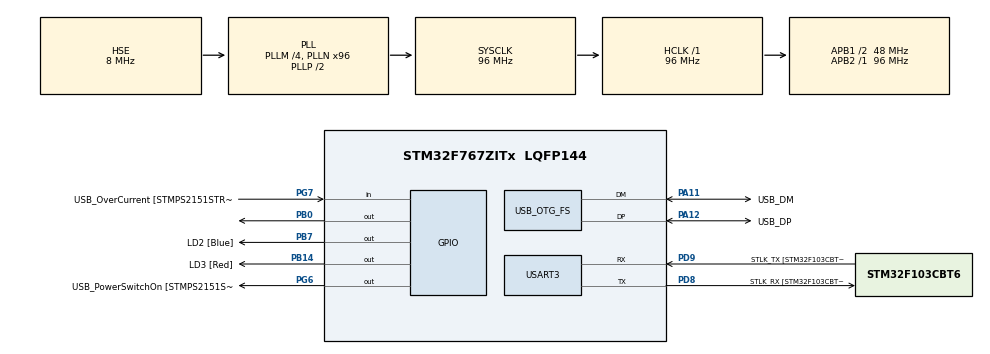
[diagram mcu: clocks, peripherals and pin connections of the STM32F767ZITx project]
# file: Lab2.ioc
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CORTEX_M7.default_mode_Activation=1
Mcu.Family=STM32F7
Mcu.Name=STM32F767ZITx
Mcu.Package=LQFP144
NVIC.OTG_FS_IRQn=true\:0\:0\:false\:false\:true\:false\:true\:true
NVIC.PriorityGroup=NVIC_PRIORITYGROUP_4
PA11.GPIO_Label=USB_DM
PA11.Mode=Device_Only
PA11.Signal=USB_OTG_FS_DM
PA12.GPIO_Label=USB_DP
PA12.Mode=Device_Only
PA12.Signal=USB_OTG_FS_DP
PA13.GPIO_Label=TMS
PA13.Mode=Serial_Wire
PA13.Signal=SYS_JTMS-SWDIO
PA14.GPIO_Label=TCK
PA14.Mode=Serial_Wire
PA14.Signal=SYS_JTCK-SWCLK
PB0.Signal=GPIO_Output
PB14.GPIO_Label=LD3 [Red]
PB14.Signal=GPIO_Output
PB7.GPIO_Label=LD2 [Blue]
PB7.Signal=GPIO_Output
PD8.GPIO_Label=STLK_RX [STM32F103CBT6_PA3]
PD8.Mode=Asynchronous
PD8.Signal=USART3_TX
PD9.GPIO_Label=STLK_TX [STM32F103CBT6_PA2]
PD9.Mode=Asynchronous
PD9.Signal=USART3_RX
PG6.GPIO_Label=USB_PowerSwitchOn [STMPS2151STR_EN]
PG6.Signal=GPIO_Output
PG7.GPIO_Label=USB_OverCurrent [STMPS2151STR_FAULT]
PG7.Signal=GPIO_Input
PH0/OSC_IN.GPIO_Label=MCO [STM32F103CBT6_PA8]
PH0/OSC_IN.Mode=HSE-External-Clock-Source
PH0/OSC_IN.Signal=RCC_OSC_IN
PH1/OSC_OUT.Mode=HSE-External-Clock-Source
PH1/OSC_OUT.Signal=RCC_OSC_OUT
ProjectManager.HeapSize=0x600
ProjectManager.StackSize=0x400
ProjectManager.TargetToolchain=STM32CubeIDE
RCC.48MHZClocksFreq_Value=24000000
RCC.AHBFreq_Value=96000000
RCC.APB1CLKDivider=RCC_HCLK_DIV2
RCC.APB1Freq_Value=48000000
RCC.APB1TimFreq_Value=96000000
RCC.APB2Freq_Value=96000000
RCC.APB2TimFreq_Value=96000000
RCC.CortexFreq_Value=96000000
RCC.HCLKFreq_Value=96000000
RCC.HSE_VALUE=8000000
RCC.HSI_VALUE=16000000
RCC.LSE_VALUE=32768
RCC.PLLM=4
RCC.PLLMUL=RCC_PLL_MUL9
RCC.PLLN=96
RCC.PLLQ=4
RCC.PRESCALERUSB=RCC_USBCLKSOURCE_PLL_DIV1_5
RCC.SYSCLKFreq_VALUE=96000000
RCC.SYSCLKSource=RCC_SYSCLKSOURCE_PLLCLK
RCC.SYSCLKSourceVirtual=RCC_SYSCLKSOURCE_PLLCLK
RCC.USBFreq_Value=48000000
RCC.VCOOutputFreq_Value=192000000
USART3.VirtualMode-Asynchronous=VM_ASYNC
USB_DEVICE.CLASS_NAME_FS=CDC
USB_DEVICE.VirtualMode-CDC_FS=Cdc
USB_DEVICE.VirtualModeFS=Cdc_FS
USB_OTG_FS.VirtualMode=Device_Only
VP_USB_DEVICE_VS_USB_DEVICE_CDC_FS.Mode=CDC_FS
board=NUCLEO-F767ZI

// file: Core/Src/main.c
/* USER CODE BEGIN Header */
/**
  ******************************************************************************
  * @file           : main.c
  * @brief          : Main program body
  ******************************************************************************
  * @attention
  *
  * Copyright (c) 2026 STMicroelectronics.
  * All rights reserved.
  *
  * This software is licensed under terms that can be found in the LICENSE file
  * in the root directory of this software component.
  * If no LICENSE file comes with this software, it is provided AS-IS.
  *
  ******************************************************************************
  */
/* USER CODE END Header */
#include "main.h"
#include "usb_device.h"

/* USER CODE BEGIN Includes */
#include "usbd_cdc_if.h"
/* USER CODE END Includes */

UART_HandleTypeDef huart3;

/* USER CODE BEGIN PV */
uint8_t TxBuffer[] = "Hello CE224.R13, this is USB CDC\r\n";
uint16_t TxBufferLen = sizeof(TxBuffer) - 1;

extern volatile uint8_t HelloReceived;
/* USER CODE END PV */

void SystemClock_Config(void);
static void MPU_Config(void);
static void MX_GPIO_Init(void);
static void MX_USART3_UART_Init(void);

int main(void)
{

  /* MPU Configuration--------------------------------------------------------*/
  MPU_Config();

  /* MCU Configuration--------------------------------------------------------*/

  /* Reset of all peripherals, Initializes the Flash interface and the Systick. */
  HAL_Init();

  /* Configure the system clock */
  SystemClock_Config();

  /* Initialize all configured peripherals */
  MX_GPIO_Init();
  MX_USART3_UART_Init();
  MX_USB_DEVICE_Init();
  /* USER CODE BEGIN 2 */
  HAL_Delay(2000);
  CDC_Transmit_FS(TxBuffer, TxBufferLen);
  /* USER CODE END 2 */

  /* Infinite loop */
  /* USER CODE BEGIN WHILE */
  while (1)
  {
	  CDC_EchoTask();
	  if (HelloReceived)
	      {
	          static uint8_t response[] = "Do you want to turn on or off light\r\n";

	          if (CDC_Transmit_FS(response, sizeof(response) - 1) == USBD_OK)
	          {
	              HelloReceived = 0;
	          }
	      }
  }
    /* USER CODE END WHILE */

}

void SystemClock_Config(void)
{
  RCC_OscInitTypeDef RCC_OscInitStruct = {0};
  RCC_ClkInitTypeDef RCC_ClkInitStruct = {0};

  /** Configure the main internal regulator output voltage
  */
  __HAL_RCC_PWR_CLK_ENABLE();
  __HAL_PWR_VOLTAGESCALING_CONFIG(PWR_REGULATOR_VOLTAGE_SCALE3);

  /** Initializes the RCC Oscillators according to the specified parameters
  * in the RCC_OscInitTypeDef structure.
  */
  RCC_OscInitStruct.OscillatorType = RCC_OSCILLATORTYPE_HSE;
  RCC_OscInitStruct.HSEState = RCC_HSE_BYPASS;
  RCC_OscInitStruct.PLL.PLLState = RCC_PLL_ON;
  RCC_OscInitStruct.PLL.PLLSource = RCC_PLLSOURCE_HSE;
  RCC_OscInitStruct.PLL.PLLM = 4;
  RCC_OscInitStruct.PLL.PLLN = 96;
  RCC_OscInitStruct.PLL.PLLP = RCC_PLLP_DIV2;
  RCC_OscInitStruct.PLL.PLLQ = 4;
  RCC_OscInitStruct.PLL.PLLR = 2;
  if (HAL_RCC_OscConfig(&RCC_OscInitStruct) != HAL_OK)
  {
    Error_Handler();
  }

  /** Activate the Over-Drive mode
  */
  if (HAL_PWREx_EnableOverDrive() != HAL_OK)
  {
    Error_Handler();
  }

  /** Initializes the CPU, AHB and APB buses clocks
  */
  RCC_ClkInitStruct.ClockType = RCC_CLOCKTYPE_HCLK|RCC_CLOCKTYPE_SYSCLK
                              |RCC_CLOCKTYPE_PCLK1|RCC_CLOCKTYPE_PCLK2;
  RCC_ClkInitStruct.SYSCLKSource = RCC_SYSCLKSOURCE_PLLCLK;
  RCC_ClkInitStruct.AHBCLKDivider = RCC_SYSCLK_DIV1;
  RCC_ClkInitStruct.APB1CLKDivider = RCC_HCLK_DIV2;
  RCC_ClkInitStruct.APB2CLKDivider = RCC_HCLK_DIV1;

  if (HAL_RCC_ClockConfig(&RCC_ClkInitStruct, FLASH_LATENCY_3) != HAL_OK)
  {
    Error_Handler();
  }
}

static void MX_USART3_UART_Init(void)
{

  huart3.Instance = USART3;
  huart3.Init.BaudRate = 115200;
  huart3.Init.WordLength = UART_WORDLENGTH_8B;
  huart3.Init.StopBits = UART_STOPBITS_1;
  huart3.Init.Parity = UART_PARITY_NONE;
  huart3.Init.Mode = UART_MODE_TX_RX;
  huart3.Init.HwFlowCtl = UART_HWCONTROL_NONE;
  huart3.Init.OverSampling = UART_OVERSAMPLING_16;
  huart3.Init.OneBitSampling = UART_ONE_BIT_SAMPLE_DISABLE;
  huart3.AdvancedInit.AdvFeatureInit = UART_ADVFEATURE_NO_INIT;
  if (HAL_UART_Init(&huart3) != HAL_OK)
  {
    Error_Handler();
  }

}

static void MX_GPIO_Init(void)
{
  GPIO_InitTypeDef GPIO_InitStruct = {0};

  /* GPIO Ports Clock Enable */
  __HAL_RCC_GPIOH_CLK_ENABLE();
  __HAL_RCC_GPIOB_CLK_ENABLE();
  __HAL_RCC_GPIOD_CLK_ENABLE();
  __HAL_RCC_GPIOG_CLK_ENABLE();
  __HAL_RCC_GPIOA_CLK_ENABLE();

  /*Configure GPIO pin Output Level */
  HAL_GPIO_WritePin(GPIOB, GPIO_PIN_0|LD3_Pin|LD2_Pin, GPIO_PIN_RESET);

  /*Configure GPIO pin Output Level */
  HAL_GPIO_WritePin(USB_PowerSwitchOn_GPIO_Port, USB_PowerSwitchOn_Pin, GPIO_PIN_RESET);

  /*Configure GPIO pins : PB0 LD3_Pin LD2_Pin */
  GPIO_InitStruct.Pin = GPIO_PIN_0|LD3_Pin|LD2_Pin;
  GPIO_InitStruct.Mode = GPIO_MODE_OUTPUT_PP;
  GPIO_InitStruct.Pull = GPIO_NOPULL;
  GPIO_InitStruct.Speed = GPIO_SPEED_FREQ_LOW;
  HAL_GPIO_Init(GPIOB, &GPIO_InitStruct);

  /*Configure GPIO pin : USB_PowerSwitchOn_Pin */
  GPIO_InitStruct.Pin = USB_PowerSwitchOn_Pin;
  GPIO_InitStruct.Mode = GPIO_MODE_OUTPUT_PP;
  GPIO_InitStruct.Pull = GPIO_NOPULL;
  GPIO_InitStruct.Speed = GPIO_SPEED_FREQ_LOW;
  HAL_GPIO_Init(USB_PowerSwitchOn_GPIO_Port, &GPIO_InitStruct);

  /*Configure GPIO pin : USB_OverCurrent_Pin */
  GPIO_InitStruct.Pin = USB_OverCurrent_Pin;
  GPIO_InitStruct.Mode = GPIO_MODE_INPUT;
  GPIO_InitStruct.Pull = GPIO_NOPULL;
  HAL_GPIO_Init(USB_OverCurrent_GPIO_Port, &GPIO_InitStruct);

}

 /* MPU Configuration */

void MPU_Config(void)
{
  MPU_Region_InitTypeDef MPU_InitStruct = {0};

  /* Disables the MPU */
  HAL_MPU_Disable();

  /** Initializes and configures the Region and the memory to be protected
  */
  MPU_InitStruct.Enable = MPU_REGION_ENABLE;
  MPU_InitStruct.Number = MPU_REGION_NUMBER0;
  MPU_InitStruct.BaseAddress = 0x0;
  MPU_InitStruct.Size = MPU_REGION_SIZE_4GB;
  MPU_InitStruct.SubRegionDisable = 0x87;
  MPU_InitStruct.TypeExtField = MPU_TEX_LEVEL0;
  MPU_InitStruct.AccessPermission = MPU_REGION_NO_ACCESS;
  MPU_InitStruct.DisableExec = MPU_INSTRUCTION_ACCESS_DISABLE;
  MPU_InitStruct.IsShareable = MPU_ACCESS_SHAREABLE;
  MPU_InitStruct.IsCacheable = MPU_ACCESS_NOT_CACHEABLE;
  MPU_InitStruct.IsBufferable = MPU_ACCESS_NOT_BUFFERABLE;

  HAL_MPU_ConfigRegion(&MPU_InitStruct);
  /* Enables the MPU */
  HAL_MPU_Enable(MPU_PRIVILEGED_DEFAULT);

}

void Error_Handler(void)
{
  __disable_irq();
  while (1)
  {
  }
}
